# PBIST register map
Vendor: Texas Instruments
Peripheral module from a debugger description file (folder awr29xx).
Registers are 32-bit, access not given, no defined reset value unless marked. A register's access mark holds for its fields unless they carry their own. Offsets are as the file gives them; lines under a group give offsets from that group; [hi:lo] are bit positions; {n}, {i} and the like mark numbered series; 'fields as' and 'values as' point back to an identical list; <NAME> marks a mode.

## PBIST
{0x100+4i} PBIST_A{i} (i=0..3) — Variable Address Register{i}
{0x110+4i} PBIST_L{i} (i=0..3) — Variable Loop Count Register L{i}
0x120 PBIST_DD10 — DD0 Data Register 16 (D0)
0x124 PBIST_DE10 — DE0 Data Register 16 (D0)
{0x130+4i} PBIST_CA{i} (i=0..3) — Constant Address Register{i}
{0x140+4i} PBIST_CL{i} (i=0..3) — Constant Loop Count Register{i}
0x150 PBIST_CI0 — Constant Increment Register0
0x154 PBIST_CI1 — Constant Increment Register1
0x158 PBIST_CI2 16-bit rw — Constant Increment Register2
  [15:0] PBIST_CI2 — TI Internal Register.Reserved for HW RnD
0x15C PBIST_CI3 16-bit rw — Constant Increment Register3
  [15:0] PBIST_CI3 — TI Internal Register.Reserved for HW RnD
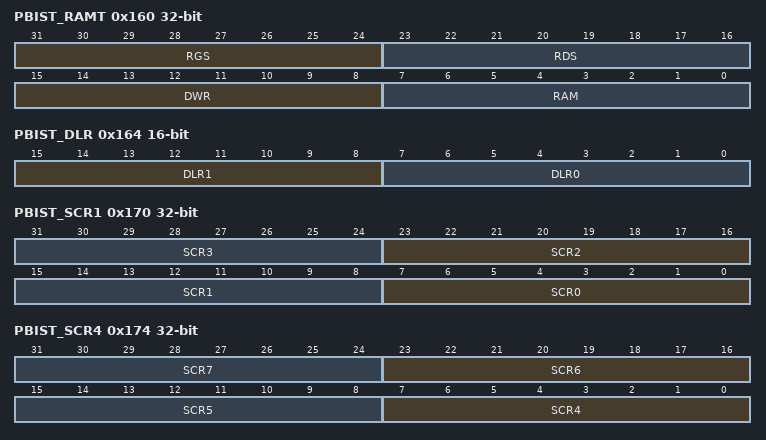
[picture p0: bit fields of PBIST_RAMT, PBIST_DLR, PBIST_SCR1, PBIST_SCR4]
0x160 PBIST_RAMT rw — RAM Configuration (RAMT -RAM)
  [31:24] RGS — TI Internal Register.Reserved for HW RnD These registers do not have a default value after reset.
  [23:16] RDS — TI Internal Register.Reserved for HW RnD These registers do not have a default value after reset.
  [15:8] DWR — TI Internal Register.Reserved for HW RnD These registers do not have a default value after reset.
  [7:0] RAM — TI Internal Register.Reserved for HW RnD These registers do not have a default value after reset.
0x164 PBIST_DLR 16-bit rw — Datalogger 0
  [15:8] DLR1 — Datalogger Register [8] : Reserevd [9] : Default Testing Mode. When in this mode, ROM-based testing is kicked off. If the intention is to perform go/no-go testing via config, write to both this bit and bit [2] of the Datalogger Register simultaneously [15:10] : Reserevd
  [7:0] DLR0 — Datalogger Register [1:0] : Reserved [2] : ROM-based testing mode. Setting this bit to 1 enables the PBIST controller to execute test algorithms that are stored in the PBIST ROM [3] : Do not change this bit from its default value of 1 [4] : Config access mode. Setting this bit allows the host processor to configure the PBIST controller registers [7:5] : Reserved
0x168 PBIST_CMS 4-bit rw — Clock mux select
  [3:0] PBIST_CMS — TI Internal Register.Reserved for HW RnD These registers do not have a default value after reset.
0x16C PBIST_PC 5-bit rw — Program Control
  [4:0] PBIST_PC — TI Internal Register.Reserved for HW RnD
0x170 PBIST_SCR1 rw — Address Scramble 0 -3
  [8n+7:8n] SCR{n} (n=0..3) — TI Internal Register.Reserved for HW RnD
0x174 PBIST_SCR4 rw — Address Scramble 4-7
  [8n-25:8n-32] SCR{n} (n=4..7) — TI Internal Register.Reserved for HW RnD
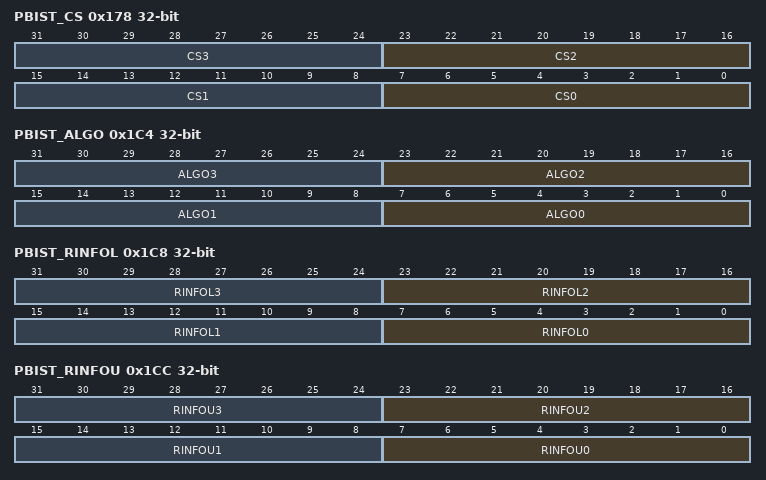
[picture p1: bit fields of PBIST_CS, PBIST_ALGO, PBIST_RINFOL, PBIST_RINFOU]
0x178 PBIST_CS rw — Chip Select 0
  [8n+7:8n] CS{n} (n=0..3) — TI Internal Register.Reserved for HW RnD
0x17C PBIST_FDLY 8-bit rw — Fail Delay
  [7:0] PBIST_FDLY — TI Internal Register.Reserved for HW RnD
0x180 PBIST_PACT 1-bit rw — Pbist Active
  [0] PBIST_PACT — Pbist Active/ROM Clock Enable Register [0]: This bit must be set to turn on internal PBIST clocks. Setting this bit asserts an internal signal that is used as the clock gate enable. As long as this bit is 0, any access to PBIST will not go through, and PBIST will remain in an almost zero-power mode. Value 0 = Disable internal PBIST clocks Value 1 = Enable internal PBIST clocks
0x184 PBIST_ID 5-bit rw
  [4:0] PBIST_ID — PBIST ID. This is a unique ID assigned to each PBIST controller in a device with multiple PBIST controllers. The value of this register does not affect the functionality of the CPU interface.
0x188 PBIST_OVR — PBIST Overrides
0x190 PBIST_FSFR0 1-bit ro — Fail status fail - port 0
  [0] PBIST_FSFR0 — Fail Status Fail Register- Port 0 This register indicates if a failure occurred during a memory self-test. Value 0 = No failure occurred Value 1 = Indicates a failure
0x194 PBIST_FSFR1 1-bit ro — Fail status fail - port 1
  [0] PBIST_FSFR1 — Fail Status Fail Register- Port 1 This register indicates if a failure occurred during a memory self-test. Value 0 = No failure occurred Value 1 = Indicates a failure
0x198 PBIST_FSRCR0 4-bit ro — Fail Count fail - port 0
  [3:0] PBIST_FSRCR0 — Fail Status Count - Port 0 These registers keep count of the number of failures observed during the memory self-test. The PBIST controller stops executing the memory self-test whenever a failure occurs in any memory instance for any of the test algorithms. The value in gets incremented by one whenever a failure occurs
0x19C PBIST_FSRCR1 4-bit ro — Fail Count fail - port 1
  [3:0] PBIST_FSRCR1 — Fail Status Count - Port 1 These registers keep count of the number of failures observed during the memory self-test. The PBIST controller stops executing the memory self-test whenever a failure occurs in any memory instance for any of the test algorithms. The value in gets incremented by one whenever a failure occurs
0x1A0 PBIST_FSRA0 — Fail status address - port 0
0x1A4 PBIST_FSRA1 16-bit ro — Fail status address - port 1
  [15:0] PBIST_FSRA1 — TI Internal Register.Reserved for HW RnD
0x1A8 PBIST_FSRDL0 ro — Fail status Data - port 0
  [31:0] PBIST_FSRDL0 — TI Internal Register.Reserved for HW RnD
0x1B0 PBIST_FSRDL1 ro — Fail status Data - port 1
  [31:0] PBIST_FSRDL1 — TI Internal Register.Reserved for HW RnD
0x1B4 PBIST_MARGIN — Margin Mode
0x1B8 PBIST_WRENZ — WRENZ
0x1BC PBIST_PGS — PAGE/PGS
0x1C0 PBIST_ROM 2-bit rw — Rom Mask
  [1:0] PBIST_ROM — Rom Mask . This two-bit register sets appropriate ROM access modes for the PBIST controller. Value 0h = No information is used from ROM Value 1h = Only RAM Group information from ROM Vaule 2h = Only Algorithm information from ROM Value 3h = Both Algorithm and RAM information from ROM. This option should be selected for application self-test.
0x1C4 PBIST_ALGO rw — ROM Algorithm Mask 0
  [8n+7:8n] ALGO{n} (n=0..3) — This register is used to indicate the algorithm(s) to be used for the memory self-test routine. Each bit corresponds to a specific algorithm. Writing a value 1 to the particular bit, enables the corresponding algorithm. Writing a value 0 to the particular bit, disables the corresponding algorithm.
0x1C8 PBIST_RINFOL rw — RAM Info Mask Lower 0
  [8n+7:8n] RINFOL{n} (n=0..3) — This register is to select memory groups to run the algorithms selected in the PBIST_ALGO register. For an algorithmto be executed on a particular memory group, the corresponding bit in this register must be set to 1. The default value of this register is all 1s, which means all the memory groups are selected. Writing a value 0 to the particular bit, disables the corresponding memory group.
0x1CC PBIST_RINFOU rw — RAM Info Mask Upper 0
  [8n+7:8n] RINFOU{n} (n=0..3) — This register is to select memory groups to run the algorithms selected in the PBIST_ALGO register. For an algorithmto be executed on a particular memory group, the corresponding bit in this register must be set to 1. The default value of this register is all 1s, which means all the memory groups are selected. Writing a value 0 to the particular bit, disables the corresponding memory group.
